VERSION ""

NS_ :

BS_:

BU_: XXX

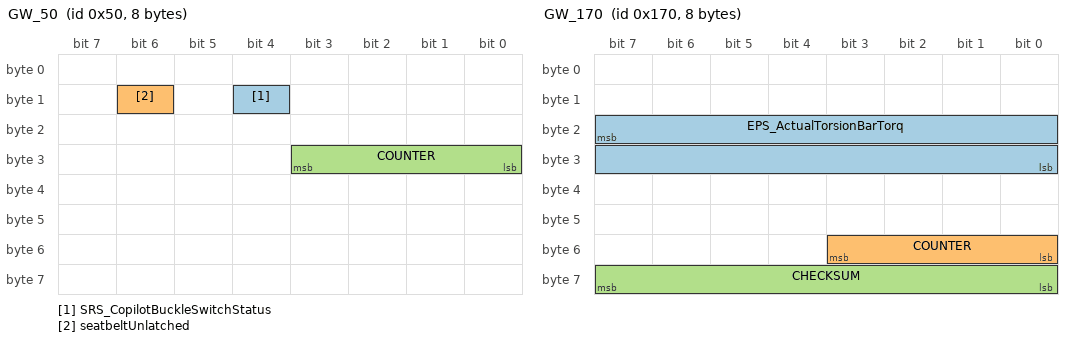
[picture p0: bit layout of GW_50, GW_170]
BO_ 80 GW_50: 8 XXX
 SG_ SRS_CopilotBuckleSwitchStatus : 12|1@0+ (1,0) [0|1] "" XXX
 SG_ seatbeltUnlatched : 14|1@0+ (1,0) [0|1] "" XXX
 SG_ COUNTER : 27|4@0+ (1,0) [0|15] "" XXX

BO_ 368 GW_170: 8 ESP
 SG_ EPS_ActualTorsionBarTorq : 23|16@0+ (1,-5533) [0|65535] "" XXX
 SG_ COUNTER : 51|4@0+ (1,0) [0|15] "" XXX
 SG_ CHECKSUM : 63|8@0+ (1,0) [0|255] "" XXX

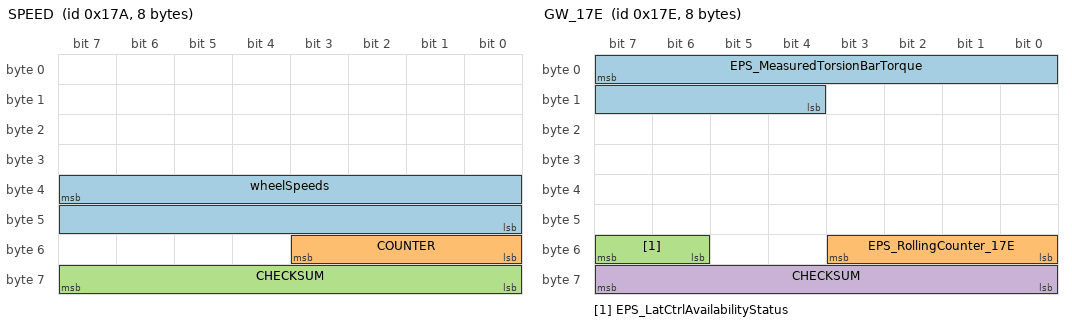
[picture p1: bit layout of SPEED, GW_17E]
BO_ 378 SPEED: 8 XXX
 SG_ wheelSpeeds : 39|16@0+ (0.05,0) [0|250] "km/h" XXX
 SG_ COUNTER : 51|4@0+ (1,0) [0|15] "" XXX
 SG_ CHECKSUM : 63|8@0+ (1,0) [0|255] "" XXX

BO_ 382 GW_17E: 8 XXX
 SG_ EPS_MeasuredTorsionBarTorque : 7|12@0+ (0.001,0) [0|4095] "" XXX
 SG_ EPS_RollingCounter_17E : 51|4@0+ (1,0) [0|15] "" XXX
 SG_ EPS_LatCtrlAvailabilityStatus : 55|2@0+ (1,0) [0|3] "" XXX
 SG_ CHECKSUM : 63|8@0+ (1,0) [0|255] "" XXX

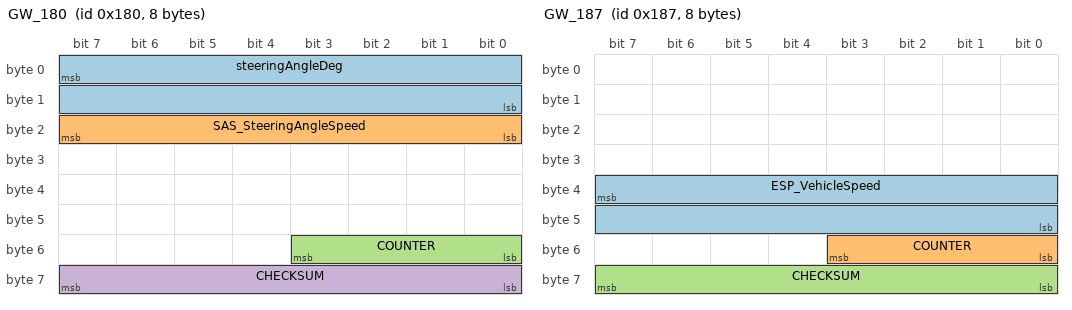
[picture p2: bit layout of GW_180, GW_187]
BO_ 384 GW_180: 8 XXX
 SG_ steeringAngleDeg : 7|16@0- (0.1,0) [-476|476] "deg" XXX
 SG_ SAS_SteeringAngleSpeed : 23|8@0+ (1,0) [0|255] "" XXX
 SG_ COUNTER : 51|4@0+ (1,0) [0|15] "" XXX
 SG_ CHECKSUM : 63|8@0+ (1,0) [0|255] "" XXX

BO_ 388 NEW_MSG_184: 8 XXX

BO_ 391 GW_187: 8 XXX
 SG_ ESP_VehicleSpeed : 39|16@0+ (0.05,0) [0|65535] "km/h" XXX
 SG_ COUNTER : 51|4@0+ (1,0) [0|15] "" XXX
 SG_ CHECKSUM : 63|8@0+ (1,0) [0|255] "" XXX

BO_ 392 NEW_MSG_188: 8 XXX
 SG_ NEW_SIGNAL_1 : 7|16@0+ (1,0) [0|65535] "" XXX

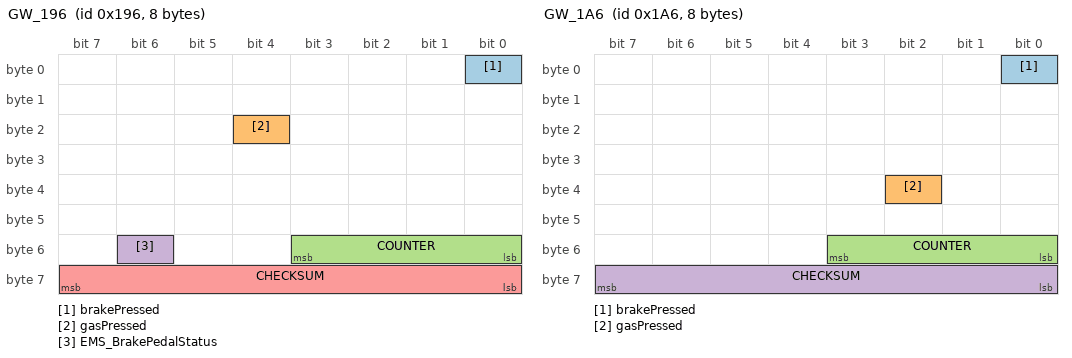
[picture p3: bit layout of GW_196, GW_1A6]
BO_ 406 GW_196: 8 XXX
 SG_ brakePressed : 0|1@0+ (1,0) [0|1] "" XXX
 SG_ gasPressed : 20|1@0+ (1,0) [0|1] "" XXX
 SG_ COUNTER : 51|4@0+ (1,0) [0|15] "" XXX
 SG_ EMS_BrakePedalStatus : 54|1@0+ (1,0) [0|1] "" XXX
 SG_ CHECKSUM : 63|8@0+ (1,0) [0|255] "" XXX

BO_ 422 GW_1A6: 8 XXX
 SG_ brakePressed : 0|1@0+ (1,0) [0|1] "" XXX
 SG_ gasPressed : 34|1@0+ (1,0) [0|1] "" XXX
 SG_ COUNTER : 51|4@0+ (1,0) [0|15] "" XXX
 SG_ CHECKSUM : 63|8@0+ (1,0) [0|255] "" XXX

BO_ 442 GW_1BA: 32 XXX
 SG_ STEER_LIMIT_Down : 7|8@0+ (1,0) [0|255] "" XXX
 SG_ STEER_LIMIT_Up : 15|8@0+ (1,0) [0|255] "" XXX
 SG_ ACC_SteeringAngleReq_1BA : 16|1@0+ (1,0) [0|1] "" XXX
 SG_ ACC_SteeringAngleSub_1BA : 31|16@0- (0.1,0) [0|65535] "" XXX
 SG_ Counter_1BA : 51|4@0+ (1,0) [0|15] "" XXX
 SG_ CHECKSUM : 63|8@0+ (1,0) [0|255] "" XXX

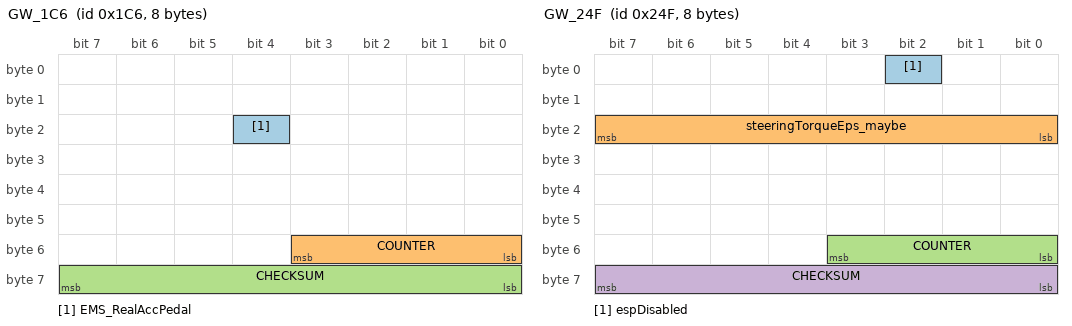
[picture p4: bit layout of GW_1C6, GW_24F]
BO_ 454 GW_1C6: 8 XXX
 SG_ EMS_RealAccPedal : 20|1@0+ (1,0) [0|1] "" XXX
 SG_ COUNTER : 51|4@0+ (1,0) [0|15] "" XXX
 SG_ CHECKSUM : 63|8@0+ (1,0) [0|255] "" XXX

BO_ 518 NEW_MSG_206: 8 XXX
 SG_ NEW_SIGNAL_1 : 7|16@0+ (0.78125,0) [0|65535] "" XXX

BO_ 520 NEW_MSG_208: 8 XXX
 SG_ NEW_SIGNAL_1 : 7|16@0+ (0.78125,0) [0|65535] "" XXX

BO_ 580 GW_244: 32 XXX
 SG_ ACC_Acceleration_24E : 7|16@0- (0.001,-25.6) [-10|10] "m/s2" XXX
 SG_ ACC_AEBCtrlType : 34|3@0+ (1,0) [0|7] "" XXX
 SG_ ACC_FCWPreWarning : 35|1@0+ (1,0) [0|1] "" XXX
 SG_ ACC_ACCEnable : 44|1@0+ (1,0) [0|1] "" XXX
 SG_ ACC_RollingCounter_24E : 51|4@0+ (1,0) [0|15] "" XXX
 SG_ ACC_ACCMode : 54|3@0+ (1,0) [0|7] "" XXX
 SG_ ACC_ACCReq : 55|1@0+ (1,0) [0|1] "" XXX
 SG_ CHECKSUM : 63|8@0+ (1,0) [0|255] "" XXX
 SG_ sig_099 : 103|16@0- (0.001,0) [-32|32] "" XXX
 SG_ COUNTER_1 : 115|4@0+ (1,0) [0|15] "" XXX
 SG_ CHECKSUM_1 : 127|8@0+ (1,0) [0|255] "" XXX

BO_ 588 NEW_MSG_24C: 8 XXX
 SG_ NEW_SIGNAL_1 : 7|16@0+ (1,0) [0|65535] "" XXX

BO_ 591 GW_24F: 8 XXX
 SG_ espDisabled : 2|1@0+ (1,0) [0|1] "" XXX
 SG_ steeringTorqueEps_maybe : 23|8@0- (0.1,0) [0|255] "" XXX
 SG_ COUNTER : 51|4@0+ (1,0) [0|15] "" XXX
 SG_ CHECKSUM : 63|8@0+ (1,0) [0|255] "" XXX

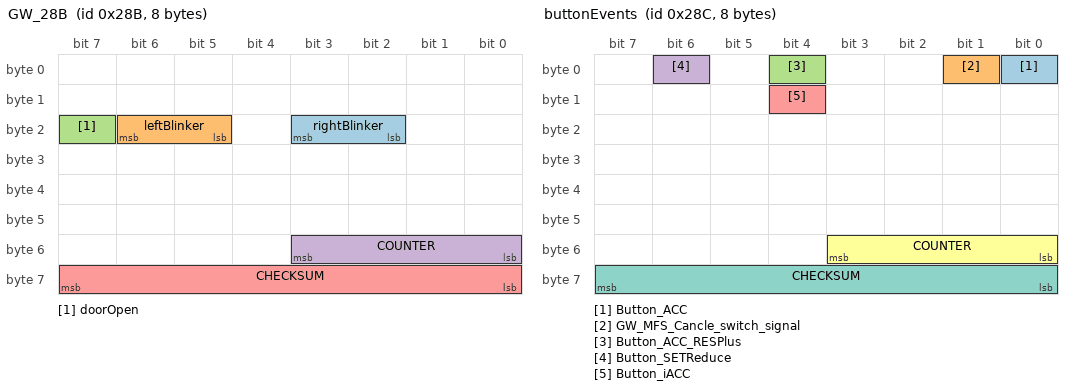
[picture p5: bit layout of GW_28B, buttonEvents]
BO_ 651 GW_28B: 8 XXX
 SG_ rightBlinker : 19|2@0+ (1,0) [0|3] "" XXX
 SG_ leftBlinker : 22|2@0+ (1,0) [0|3] "" XXX
 SG_ doorOpen : 23|1@0+ (1,0) [0|1] "" XXX
 SG_ COUNTER : 51|4@0+ (1,0) [0|15] "" XXX
 SG_ CHECKSUM : 63|8@0+ (1,0) [0|255] "" XXX

BO_ 652 buttonEvents: 8 XXX
 SG_ Button_ACC : 0|1@0+ (1,0) [0|1] "" XXX
 SG_ GW_MFS_Cancle_switch_signal : 1|1@0+ (1,0) [0|1] "" XXX
 SG_ Button_ACC_RESPlus : 4|1@0+ (1,0) [0|1] "" XXX
 SG_ Button_SETReduce : 6|1@0+ (1,0) [0|1] "" XXX
 SG_ Button_iACC : 12|1@0+ (1,0) [0|1] "" XXX
 SG_ COUNTER : 51|4@0+ (1,0) [0|15] "" XXX
 SG_ CHECKSUM : 63|8@0+ (1,0) [0|255] "" XXX

BO_ 775 GW_307: 64 XXX
 SG_ vCruise : 7|16@0+ (0.0078125,0) [0|250] "" XXX
 SG_ ACC_DistanceLevel : 17|2@0+ (1,0) [0|3] "" XXX
 SG_ Counter_35E : 51|4@0+ (1,0) [0|15] "" XXX
 SG_ CHECKSUM_1 : 63|8@0+ (1,0) [0|255] "" XXX
 SG_ COUNTER_2 : 115|4@0+ (1,0) [0|15] "" XXX
 SG_ CHECKSUM_2 : 127|8@0+ (1,0) [0|255] "" XXX
 SG_ COUNTER_3 : 179|4@0+ (1,0) [0|15] "" XXX
 SG_ CHECKSUM_3 : 191|8@0+ (1,0) [0|255] "" XXX
 SG_ COUNTER_4 : 243|4@0+ (1,0) [0|15] "" XXX
 SG_ CHECKSUM_4 : 255|8@0+ (1,0) [0|255] "" XXX

BO_ 794 GW_31A: 64 XXX
 SG_ ACC_IACCHWAMode : 45|3@0+ (1,0) [0|7] "" XXX
 SG_ Counter_36D : 51|4@0+ (1,0) [0|15] "" XXX
 SG_ CHECKSUM_1 : 63|8@0+ (1,0) [0|255] "" XXX
 SG_ cruiseState : 68|1@0+ (1,0) [0|1] "" XXX
 SG_ steeringPressed : 96|1@0+ (1,0) [0|1] "" XXX
 SG_ COUNTER_2 : 115|4@0+ (1,0) [0|15] "" XXX
 SG_ CHECKSUM_2 : 127|8@0+ (1,0) [0|255] "" XXX
 SG_ COUNTER_3 : 179|4@0+ (1,0) [0|15] "" XXX
 SG_ CHECKSUM_3 : 191|8@0+ (1,0) [0|255] "" XXX
 SG_ COUNTER_4 : 243|4@0+ (1,0) [0|15] "" XXX
 SG_ CHECKSUM_4 : 255|8@0+ (1,0) [0|255] "" XXX

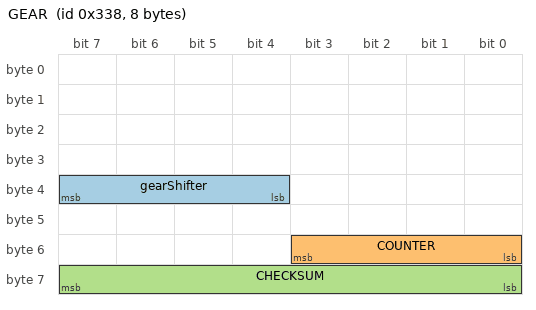
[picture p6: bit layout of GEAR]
BO_ 824 GEAR: 8 XXX
 SG_ gearShifter : 39|4@0+ (1,-7) [0|15] "" XXX
 SG_ COUNTER : 51|4@0+ (1,0) [0|15] "" XXX
 SG_ CHECKSUM : 63|8@0+ (1,0) [0|255] "" XXX

BO_ 999 NEW_MSG_3E7: 8 XXX
 SG_ NEW_SIGNAL_1 : 7|16@0+ (0.78,0) [0|65535] "" XXX

CM_ BO_ 378 "Z6 idd speed";
CM_ SG_ 384 steeringAngleDeg "1";
CM_ SG_ 422 brakePressed "IDD";
CM_ BO_ 591 "EPS_591";
CM_ SG_ 651 rightBlinker "2 right";
CM_ SG_ 651 leftBlinker "1 left";
CM_ SG_ 651 doorOpen "0 open";
CM_ BO_ 652 "GW_28C";
CM_ BO_ 824 "gear info";
VAL_ 824 gearShifter 2 "N" 1 "R" 3 "D" 0 "P";
